VERSION ""

NS_ :

BS_:
BU_: K16_BECM K73_TCIC K9_BCM K43_PSCM K17_EBCM K20_ECM K114B_HPCM NEO K124_ASCM EPB
BO_ 328 PSCM_148: 1 K43_PSCM

BO_ 381 ESPStatus: 6 K20_ECM
   SG_ TractionControlOn : 5|1@0+ (1,0) [0|0] "" NEO
   SG_ MSG17D_AccPower : 35|12@0- (1,0) [0|0] "" NEO

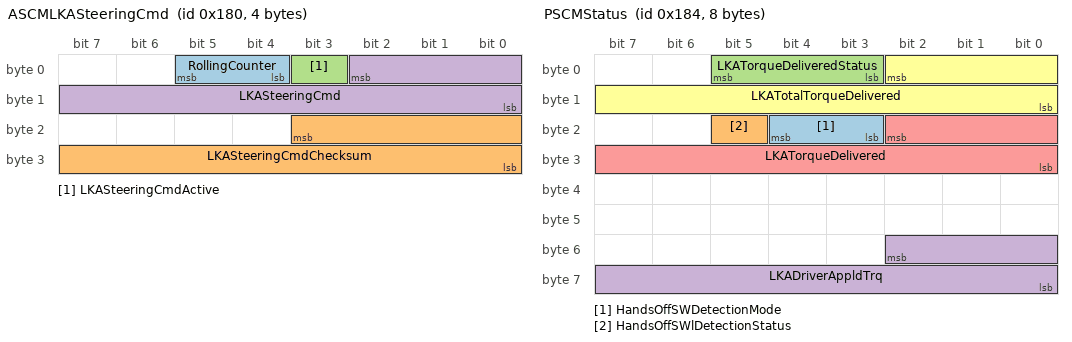
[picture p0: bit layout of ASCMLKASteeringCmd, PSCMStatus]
BO_ 384 ASCMLKASteeringCmd: 4 NEO
   SG_ RollingCounter : 5|2@0+ (1,0) [0|0] "" NEO
   SG_ LKASteeringCmdChecksum : 19|12@0+ (1,0) [0|0] "" NEO
   SG_ LKASteeringCmdActive : 3|1@0+ (1,0) [0|0] "" NEO
   SG_ LKASteeringCmd : 2|11@0- (1,0) [0|0] "" NEO

BO_ 388 PSCMStatus: 8 K43_PSCM
   SG_ HandsOffSWDetectionMode : 20|2@0+ (1,0) [0|3] "" NEO
   SG_ HandsOffSWlDetectionStatus : 21|1@0+ (1,0) [0|1] "" NEO
   SG_ LKATorqueDeliveredStatus : 5|3@0+ (1,0) [0|7] "" NEO
   SG_ LKADriverAppldTrq : 50|11@0- (0.01,0) [-10.24|10.23] "Nm" NEO
   SG_ LKATorqueDelivered : 18|11@0- (0.01,0) [0|1] "" NEO
   SG_ LKATotalTorqueDelivered : 2|11@0- (0.01,0) [-10.24|10.23] "Nm" NEO

BO_ 417 AcceleratorPedal: 8 Vector__XXX
   SG_ AcceleratorPedal : 55|8@0+ (1,0) [0|0] "" NEO

BO_ 451 GasAndAcc: 8 Vector__XXX
   SG_ GasPedalAndAcc2 : 55|8@0+ (1,0) [0|0] "" NEO

BO_ 452 AcceleratorPedal2: 8 Vector__XXX
   SG_ CruiseState : 15|3@0+ (1,0) [0|7] "" NEO
   SG_ AcceleratorPedal2 : 47|8@0+ (1,0) [0|0] "" NEO

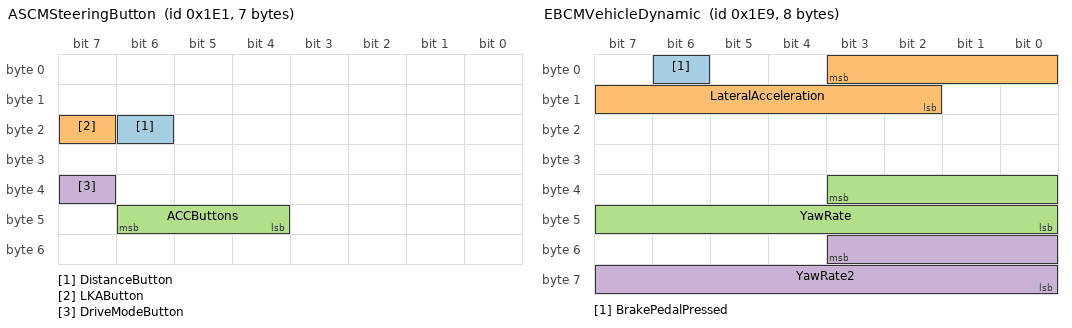
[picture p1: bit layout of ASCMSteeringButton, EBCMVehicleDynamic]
BO_ 481 ASCMSteeringButton: 7 K124_ASCM
   SG_ DistanceButton : 22|1@0+ (1,0) [0|0] "" NEO
   SG_ LKAButton : 23|1@0+ (1,0) [0|0] "" NEO
   SG_ ACCButtons : 46|3@0+ (1,0) [0|0] "" NEO
   SG_ DriveModeButton : 39|1@0+ (1,0) [0|1] "" Vector__XXX

BO_ 485 PSCMSteeringAngle: 8 K43_PSCM
   SG_ SteeringWheelAngle : 15|16@0- (0.0625,0) [-540|540] "deg" NEO
   SG_ SteeringWheelRate : 27|12@0- (0.5,0) [-100|100] "deg/s" NEO

BO_ 489 EBCMVehicleDynamic: 8 K17_EBCM
   SG_ BrakePedalPressed : 6|1@0+ (1,0) [0|0] "" NEO
   SG_ LateralAcceleration : 3|10@0- (0.161,0) [-2047|2047] "m/s2" NEO
   SG_ YawRate : 35|12@0- (0.625,0) [0|1] "" NEO
   SG_ YawRate2 : 51|12@0- (0.0625,0) [-2047|2047] "grad/s" NEO

BO_ 560 EPBStatus: 8 EPB
   SG_ EPBClosed : 12|1@0+ (1,0) [0|1] "" NEO

BO_ 711 BECMBatteryVoltageCurrent: 6 K17_EBCM
   SG_ HVBatteryVoltage : 31|12@0+ (0.125,0) [0|511.875] "V" NEO
   SG_ HVBatteryCurrent : 12|13@0- (0.15,0) [-614.4|614.25] "A" NEO

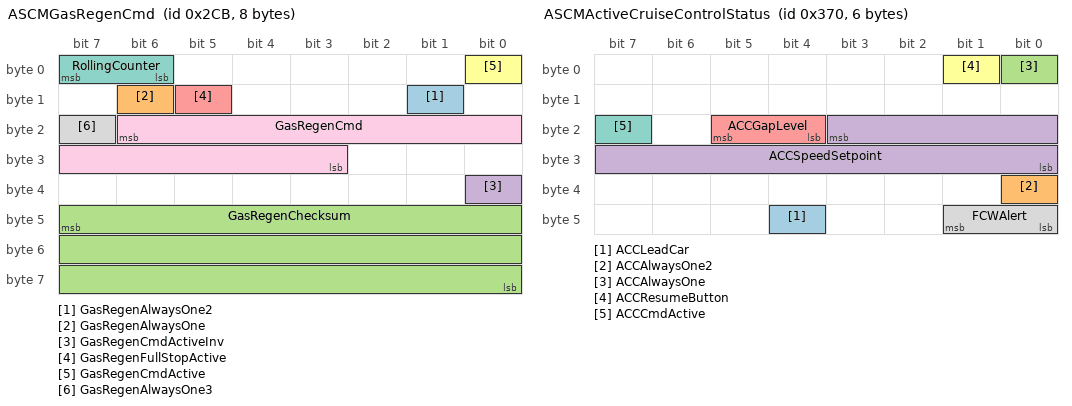
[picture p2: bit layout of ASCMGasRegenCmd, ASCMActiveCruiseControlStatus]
BO_ 715 ASCMGasRegenCmd: 8 K124_ASCM
   SG_ GasRegenAlwaysOne2 : 9|1@0+ (1,0) [0|1] "" NEO
   SG_ GasRegenAlwaysOne : 14|1@0+ (1,0) [0|1] "" NEO
   SG_ GasRegenChecksum : 47|24@0+ (1,0) [0|0] "" NEO
   SG_ GasRegenCmdActiveInv : 32|1@0+ (1,0) [0|0] "" NEO
   SG_ GasRegenFullStopActive : 13|1@0+ (1,0) [0|0] "" NEO
   SG_ GasRegenCmdActive : 0|1@0+ (1,0) [0|0] "" NEO
   SG_ RollingCounter : 7|2@0+ (1,0) [0|0] "" NEO
   SG_ GasRegenAlwaysOne3 : 23|1@0+ (1,0) [0|1] "" NEO
   SG_ GasRegenCmd : 22|12@0+ (1,0) [0|0] "" NEO

BO_ 717 ASCM_2CD: 5 K124_ASCM

BO_ 810 TCICOnStarGPSPosition: 8 K73_TCIC
   SG_ GPSLongitude : 39|32@0+ (1,0) [0|0] "milliarcsecond" NEO
   SG_ GPSLatitude : 7|32@0+ (1,0) [0|0] "milliarcsecond" NEO

BO_ 840 EBCMWheelSpdFront: 4 K17_EBCM
   SG_ FLWheelSpd : 7|16@0+ (0.0311,0) [0|255] "km/h" NEO
   SG_ FRWheelSpd : 23|16@0+ (0.0311,0) [0|255] "km/h" NEO

BO_ 842 EBCMWheelSpdRear: 4 K17_EBCM
   SG_ RLWheelSpd : 7|16@0+ (0.0311,0) [0|255] "km/h" NEO
   SG_ RRWheelSpd : 23|16@0+ (0.0311,0) [0|255] "km/h" NEO

BO_ 869 ASCM_365: 4 K124_ASCM

BO_ 880 ASCMActiveCruiseControlStatus: 6 K124_ASCM
   SG_ ACCLeadCar : 44|1@0+ (1,0) [0|0] "" Vector__XXX
   SG_ ACCAlwaysOne2 : 32|1@0+ (1,0) [0|0] "" Vector__XXX
   SG_ ACCAlwaysOne : 0|1@0+ (1,0) [0|0] "" Vector__XXX
   SG_ ACCSpeedSetpoint : 19|12@0+ (1,0) [0|0] "km/h" NEO
   SG_ ACCGapLevel : 21|2@0+ (1,0) [0|0] "" NEO
   SG_ ACCResumeButton : 1|1@0+ (1,0) [0|0] "" NEO
   SG_ ACCCmdActive : 23|1@0+ (1,0) [0|0] "" NEO
   SG_ FCWAlert : 41|2@0+ (1,0) [0|3] "" Vector__XXX

BO_ 1001 ECMVehicleSpeed: 8 K20_ECM
   SG_ VehicleSpeed : 7|16@0+ (0.01,0) [0|0] "mph" NEO

BO_ 1033 ASCMKeepAlive: 7 NEO
   SG_ ASCMKeepAliveAllZero : 7|56@0+ (1,0) [0|0] "" NEO

BO_ 1034 ASCM_40A: 7 K124_ASCM

BO_ 1217 ECMEngineCoolantTemp: 8 K20_ECM
   SG_ EngineCoolantTemp : 23|8@0+ (1,-40) [0|0] "C" NEO

BO_ 1249 VIN_Part2: 8 K20_ECM
   SG_ VINPart2 : 7|64@0+ (1,0) [0|0] "" NEO

BO_ 1296 ASCM_510: 4 K124_ASCM

BO_ 1300 VIN_Part1: 8 K20_ECM
   SG_ VINPart1 : 7|64@0+ (1,0) [0|0] "" NEO

BO_ 1912 PSCM_778: 8 K43_PSCM

BO_ 1930 ASCM_78A: 7 K124_ASCM

BO_ 512 Battery_Module_1: 8 K16_BECM
   SG_ Voltage_1_0_A m0 : 4|12@1+ (0.00125,0) [0|0] "" K16_BECM
   SG_ Voltage_1_0_B m0 : 20|12@1+ (0.00125,0) [0|0] "" K16_BECM
   SG_ Voltage_1_0_C m0 : 36|12@1+ (0.00125,0) [0|0] "" K16_BECM
   SG_ Voltage_1_1_A m1 : 4|12@1+ (0.00125,0) [0|0] "" K16_BECM
   SG_ Voltage_1_1_B m1 : 20|12@1+ (0.00125,0) [0|0] "" K16_BECM
   SG_ Voltage_1_1_C m1 : 36|12@1+ (0.00125,0) [0|0] "" K16_BECM
   SG_ Voltage_1_2_A m2 : 4|12@1+ (0.00125,0) [0|0] "" K16_BECM
   SG_ Voltage_1_2_B m2 : 20|12@1+ (0.00125,0) [0|0] "" K16_BECM
   SG_ Voltage_1_2_C m2 : 36|12@1+ (0.00125,0) [0|0] "" K16_BECM
   SG_ Voltage_1_3_A m3 : 4|12@1+ (0.00125,0) [0|0] "" K16_BECM
   SG_ Voltage_1_3_B m3 : 20|12@1+ (0.00125,0) [0|0] "" K16_BECM
   SG_ Voltage_1_3_C m3 : 36|12@1+ (0.00125,0) [0|0] "" K16_BECM
   SG_ Voltage_1_4_A m4 : 4|12@1+ (0.00125,0) [0|0] "" K16_BECM
   SG_ Voltage_1_4_B m4 : 20|12@1+ (0.00125,0) [0|0] "" K16_BECM
   SG_ Voltage_1_4_C m4 : 36|12@1+ (0.00125,0) [0|0] "" K16_BECM
   SG_ Voltage_1_5_A m5 : 4|12@1+ (0.00125,0) [0|0] "" K16_BECM
   SG_ Voltage_1_5_B m5 : 20|12@1+ (0.00125,0) [0|0] "" K16_BECM
   SG_ Voltage_1_5_C m5 : 36|12@1+ (0.00125,0) [0|0] "" K16_BECM
   SG_ Voltage_1_6_A m6 : 4|12@1+ (0.00125,0) [0|0] "" K16_BECM
   SG_ Voltage_1_6_B m6 : 20|12@1+ (0.00125,0) [0|0] "" K16_BECM
   SG_ Voltage_1_6_C m6 : 36|12@1+ (0.00125,0) [0|0] "" K16_BECM
   SG_ Voltage_1_7_A m7 : 4|12@1+ (0.00125,0) [0|0] "" K16_BECM
   SG_ Voltage_1_7_B m7 : 20|12@1+ (0.00125,0) [0|0] "" K16_BECM
   SG_ Voltage_1_7_C m7 : 36|12@1+ (0.00125,0) [0|0] "" K16_BECM
   SG_ Cell_Bank_Number_1 M : 53|7@1+ (1,0) [0|0] "" K16_BECM

BO_ 514 Battery_Module_2: 8 K16_BECM
   SG_ Voltage_2_0_A m0 : 4|12@1+ (0.00125,0) [0|0] "" K16_BECM
   SG_ Voltage_2_0_B m0 : 20|12@1+ (0.00125,0) [0|0] "" K16_BECM
   SG_ Voltage_2_0_C m0 : 36|12@1+ (0.00125,0) [0|0] "" K16_BECM
   SG_ Voltage_2_1_A m1 : 4|12@1+ (0.00125,0) [0|0] "" K16_BECM
   SG_ Voltage_2_1_B m1 : 20|12@1+ (0.00125,0) [0|0] "" K16_BECM
   SG_ Voltage_2_1_C m1 : 36|12@1+ (0.00125,0) [0|0] "" K16_BECM
   SG_ Voltage_2_2_A m2 : 4|12@1+ (0.00125,0) [0|0] "" K16_BECM
   SG_ Voltage_2_2_B m2 : 20|12@1+ (0.00125,0) [0|0] "" K16_BECM
   SG_ Voltage_2_2_C m2 : 36|12@1+ (0.00125,0) [0|0] "" K16_BECM
   SG_ Voltage_2_3_A m3 : 4|12@1+ (0.00125,0) [0|0] "" K16_BECM
   SG_ Voltage_2_3_B m3 : 20|12@1+ (0.00125,0) [0|0] "" K16_BECM
   SG_ Voltage_2_3_C m3 : 36|12@1+ (0.00125,0) [0|0] "" K16_BECM
   SG_ Voltage_2_4_A m4 : 4|12@1+ (0.00125,0) [0|0] "" K16_BECM
   SG_ Voltage_2_4_B m4 : 20|12@1+ (0.00125,0) [0|0] "" K16_BECM
   SG_ Voltage_2_4_C m4 : 36|12@1+ (0.00125,0) [0|0] "" K16_BECM
   SG_ Voltage_2_5_A m5 : 4|12@1+ (0.00125,0) [0|0] "" K16_BECM
   SG_ Voltage_2_5_B m5 : 20|12@1+ (0.00125,0) [0|0] "" K16_BECM
   SG_ Voltage_2_5_C m5 : 36|12@1+ (0.00125,0) [0|0] "" K16_BECM
   SG_ Voltage_2_6_A m6 : 4|12@1+ (0.00125,0) [0|0] "" K16_BECM
   SG_ Voltage_2_6_B m6 : 20|12@1+ (0.00125,0) [0|0] "" K16_BECM
   SG_ Voltage_2_6_C m6 : 36|12@1+ (0.00125,0) [0|0] "" K16_BECM
   SG_ Voltage_2_7_A m7 : 4|12@1+ (0.00125,0) [0|0] "" K16_BECM
   SG_ Voltage_2_7_B m7 : 20|12@1+ (0.00125,0) [0|0] "" K16_BECM
   SG_ Voltage_2_7_C m7 : 36|12@1+ (0.00125,0) [0|0] "" K16_BECM
   SG_ Cell_Bank_Number_2 M : 53|7@1+ (1,0) [0|0] "" K16_BECM

BO_ 516 Battery_Module_3: 8 K16_BECM
   SG_ Voltage_3_0_A m0 : 4|12@1+ (0.00125,0) [0|0] "" K16_BECM
   SG_ Voltage_3_0_B m0 : 20|12@1+ (0.00125,0) [0|0] "" K16_BECM
   SG_ Voltage_3_0_C m0 : 36|12@1+ (0.00125,0) [0|0] "" K16_BECM
   SG_ Voltage_3_1_A m1 : 4|12@1+ (0.00125,0) [0|0] "" K16_BECM
   SG_ Voltage_3_1_B m1 : 20|12@1+ (0.00125,0) [0|0] "" K16_BECM
   SG_ Voltage_3_1_C m1 : 36|12@1+ (0.00125,0) [0|0] "" K16_BECM
   SG_ Voltage_3_2_A m2 : 4|12@1+ (0.00125,0) [0|0] "" K16_BECM
   SG_ Voltage_3_2_B m2 : 20|12@1+ (0.00125,0) [0|0] "" K16_BECM
   SG_ Voltage_3_2_C m2 : 36|12@1+ (0.00125,0) [0|0] "" K16_BECM
   SG_ Voltage_3_3_A m3 : 4|12@1+ (0.00125,0) [0|0] "" K16_BECM
   SG_ Voltage_3_3_B m3 : 20|12@1+ (0.00125,0) [0|0] "" K16_BECM
   SG_ Voltage_3_3_C m3 : 36|12@1+ (0.00125,0) [0|0] "" K16_BECM
   SG_ Voltage_3_4_A m4 : 4|12@1+ (0.00125,0) [0|0] "" K16_BECM
   SG_ Voltage_3_4_B m4 : 20|12@1+ (0.00125,0) [0|0] "" K16_BECM
   SG_ Voltage_3_4_C m4 : 36|12@1+ (0.00125,0) [0|0] "" K16_BECM
   SG_ Voltage_3_5_A m5 : 4|12@1+ (0.00125,0) [0|0] "" K16_BECM
   SG_ Voltage_3_5_B m5 : 20|12@1+ (0.00125,0) [0|0] "" K16_BECM
   SG_ Voltage_3_5_C m5 : 36|12@1+ (0.00125,0) [0|0] "" K16_BECM
   SG_ Voltage_3_6_A m6 : 4|12@1+ (0.00125,0) [0|0] "" K16_BECM
   SG_ Voltage_3_6_B m6 : 20|12@1+ (0.00125,0) [0|0] "" K16_BECM
   SG_ Voltage_3_6_C m6 : 36|12@1+ (0.00125,0) [0|0] "" K16_BECM
   SG_ Voltage_3_7_A m7 : 4|12@1+ (0.00125,0) [0|0] "" K16_BECM
   SG_ Voltage_3_7_B m7 : 20|12@1+ (0.00125,0) [0|0] "" K16_BECM
   SG_ Voltage_3_7_C m7 : 36|12@1+ (0.00125,0) [0|0] "" K16_BECM
   SG_ Cell_Bank_Number_3 M : 53|7@1+ (1,0) [0|0] "" K16_BECM

BO_ 518 Battery_Module_4: 8 K16_BECM
   SG_ Voltage_4_0_A m0 : 4|12@1+ (0.00125,0) [0|0] "" K16_BECM
   SG_ Voltage_4_0_B m0 : 20|12@1+ (0.00125,0) [0|0] "" K16_BECM
   SG_ Voltage_4_0_C m0 : 36|12@1+ (0.00125,0) [0|0] "" K16_BECM
   SG_ Voltage_4_1_A m1 : 4|12@1+ (0.00125,0) [0|0] "" K16_BECM
   SG_ Voltage_4_1_B m1 : 20|12@1+ (0.00125,0) [0|0] "" K16_BECM
   SG_ Voltage_4_1_C m1 : 36|12@1+ (0.00125,0) [0|0] "" K16_BECM
   SG_ Voltage_4_2_A m2 : 4|12@1+ (0.00125,0) [0|0] "" K16_BECM
   SG_ Voltage_4_2_B m2 : 20|12@1+ (0.00125,0) [0|0] "" K16_BECM
   SG_ Voltage_4_2_C m2 : 36|12@1+ (0.00125,0) [0|0] "" K16_BECM
   SG_ Voltage_4_3_A m3 : 4|12@1+ (0.00125,0) [0|0] "" K16_BECM
   SG_ Voltage_4_3_B m3 : 20|12@1+ (0.00125,0) [0|0] "" K16_BECM
   SG_ Voltage_4_3_C m3 : 36|12@1+ (0.00125,0) [0|0] "" K16_BECM
   SG_ Voltage_4_4_A m4 : 4|12@1+ (0.00125,0) [0|0] "" K16_BECM
   SG_ Voltage_4_4_B m4 : 20|12@1+ (0.00125,0) [0|0] "" K16_BECM
   SG_ Voltage_4_4_C m4 : 36|12@1+ (0.00125,0) [0|0] "" K16_BECM
   SG_ Voltage_4_5_A m5 : 4|12@1+ (0.00125,0) [0|0] "" K16_BECM
   SG_ Voltage_4_5_B m5 : 20|12@1+ (0.00125,0) [0|0] "" K16_BECM
   SG_ Voltage_4_5_C m5 : 36|12@1+ (0.00125,0) [0|0] "" K16_BECM
   SG_ Voltage_4_6_A m6 : 4|12@1+ (0.00125,0) [0|0] "" K16_BECM
   SG_ Voltage_4_6_B m6 : 20|12@1+ (0.00125,0) [0|0] "" K16_BECM
   SG_ Voltage_4_6_C m6 : 36|12@1+ (0.00125,0) [0|0] "" K16_BECM
   SG_ Voltage_4_7_A m7 : 4|12@1+ (0.00125,0) [0|0] "" K16_BECM
   SG_ Voltage_4_7_B m7 : 20|12@1+ (0.00125,0) [0|0] "" K16_BECM
   SG_ Voltage_4_7_C m7 : 36|12@1+ (0.00125,0) [0|0] "" K16_BECM
   SG_ Cell_Bank_Number_4 M : 53|7@1+ (1,0) [0|0] "" K16_BECM

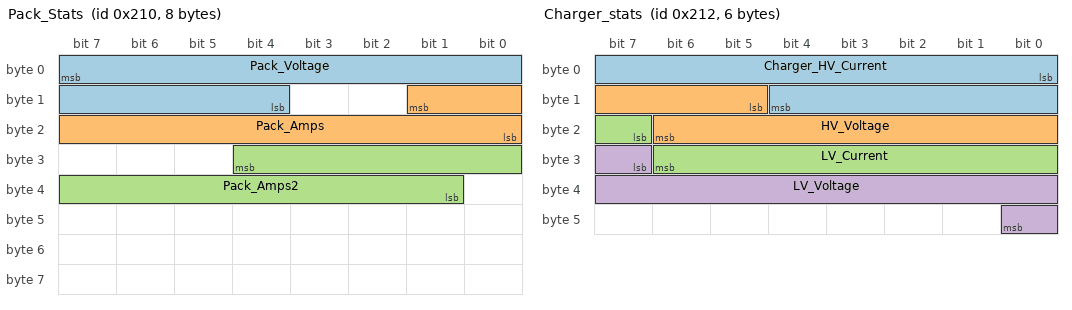
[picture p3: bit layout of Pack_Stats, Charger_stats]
BO_ 528 Pack_Stats: 8 K16_BECM
   SG_ Pack_Voltage : 7|12@0+ (0.125,0) [0|0] "" K16_BECM
   SG_ Pack_Amps : 9|10@0+ (0.1,0) [0|0] "" K16_BECM
   SG_ Pack_Amps2 : 28|12@0+ (0.05,0) [0|0] "" K16_BECM

BO_ 530 Charger_stats: 6 K16_BECM
   SG_ Charger_HV_Current : 0|13@1+ (0.05,0) [0|0] "" K16_BECM
   SG_ HV_Voltage : 13|10@1+ (0.5,0) [0|0] "" K16_BECM
   SG_ LV_Current : 23|8@1+ (0.2,0) [0|0] "" K16_BECM
   SG_ LV_Voltage : 31|10@1- (0.025,0) [0|0] "" K16_BECM

BO_ 770 Battery_temp: 8 K16_BECM
   SG_ Temp_A m0 : 8|8@1+ (0.5,-40) [0|0] "" K16_BECM
   SG_ Temp_B m0 : 16|8@1+ (0.5,-40) [0|0] "" K16_BECM
   SG_ Temp_C m0 : 24|8@1+ (0.5,-40) [0|0] "" K16_BECM
   SG_ Temp_D m0 : 32|8@1+ (0.5,-40) [0|0] "" K16_BECM
   SG_ Temp_E m0 : 40|8@1+ (0.5,-40) [0|0] "" K16_BECM
   SG_ Temp_F m0 : 48|8@1+ (0.5,-40) [0|0] "" K16_BECM
   SG_ Temp_G m1 : 8|8@1+ (0.5,-40) [0|0] "" K16_BECM
   SG_ Temp_H m1 : 16|8@1+ (0.5,-40) [0|0] "" K16_BECM
   SG_ Temp_I m1 : 24|8@1+ (0.5,-40) [0|0] "" K16_BECM
   SG_ Switch M : 2|1@1+ (1,0) [0|0] "" K16_BECM

BA_DEF_ BO_ "GenMsgBackgroundColor" STRING ;
BA_DEF_ BO_ "GenMsgForegroundColor" STRING ;
BA_DEF_DEF_ "GenMsgBackgroundColor" "#ffffff";
BA_DEF_DEF_ "GenMsgForegroundColor" "#000000";
CM_ BU_ K16_BECM "Battery Energy Control Module";
CM_ BU_ K73_TCIC "Telematics Communication Control Module";
CM_ BU_ K9_BCM "Body Control Module";
CM_ BU_ K43_PSCM "Power Steering Control Module";
CM_ BU_ K17_EBCM "Electronic Brake Control Module";
CM_ BU_ K20_ECM "Engine Control Module";
CM_ BU_ K114B_HPCM "Hybrid Powertrain Control Module";
CM_ BU_ NEO "Comma NEO";
CM_ BU_ K124_ASCM "Active Safety Control Module";
CM_ SG_ 381 MSG17D_AccPower "Need to investigate";
CM_ SG_ 451 GasPedalAndAcc2 "ACC baseline is 62";
VAL_ 384 LKASteeringCmdActive 1 "Active" 0 "Inactive";
VAL_ 388 HandsOffSWDetectionMode 2 "Failed" 1 "Enabled" 0 "Disabled";
VAL_ 388 HandsOffSWlDetectionStatus 1 "Hands On" 0 "Hands Off";
VAL_ 388 LKATorqueDeliveredStatus 3 "Failed" 2 "Temp. Limited" 1 "Active" 0 "Inactive";
VAL_ 452 CruiseState 4 "Standstill" 3 "Faulted" 1 "Active" 0 "Off";
VAL_ 481 DistanceButton 1 "Active" 0 "Inactive";
VAL_ 481 LKAButton 1 "Active" 0 "Inactive";
VAL_ 481 ACCButtons 6 "Cancel" 5 "Main" 3 "Set" 2 "Resume" 1 "None";
VAL_ 481 DriveModeButton 1 "Active" 0 "Inactive";
VAL_ 489 BrakePedalPressed 1 "Pressed" 0 "Depressed";
VAL_ 715 GasRegenCmdActiveInv 1 "Inactive" 0 "Active";
VAL_ 715 GasRegenCmdActive 1 "Active" 0 "Inactive";
VAL_ 880 ACCLeadCar 1 "Present" 0 "Not Present";
VAL_ 880 ACCGapLevel 3 "Far" 2 "Med" 1 "Near" 0 "Inactive";
VAL_ 880 ACCResumeButton 1 "Pressed" 0 "Depressed";
VAL_ 880 ACCCmdActive 1 "Active" 0 "Inactive";
